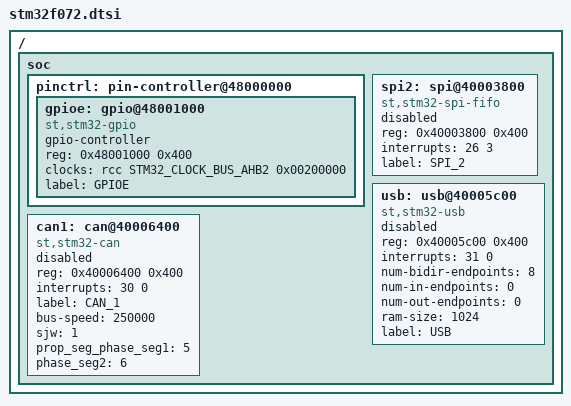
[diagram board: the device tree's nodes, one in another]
/*
 * Copyright (c) 2017 BayLibre, SAS
 *
 * SPDX-License-Identifier: Apache-2.0
 */

#include <st/stm32f0.dtsi>

/ {
	soc {
		pinctrl: pin-controller@48000000 {

			gpioe: gpio@48001000 {
				compatible = "st,stm32-gpio";
				gpio-controller;
				#gpio-cells = <2>;
				reg = <0x48001000 0x400>;
				clocks = <&rcc STM32_CLOCK_BUS_AHB2 0x00200000>;
				label = "GPIOE";
			};
		};

		spi2: spi@40003800 {
			compatible = "st,stm32-spi-fifo";
			#address-cells = <1>;
			#size-cells = <0>;
			reg = <0x40003800 0x400>;
			interrupts = <26 3>;
			status = "disabled";
			label = "SPI_2";
		};

		usb: usb@40005c00 {
			compatible = "st,stm32-usb";
			reg = <0x40005c00 0x400>;
			interrupts = <31 0>;
			interrupt-names = "usb";
			num-bidir-endpoints = <8>;
			num-in-endpoints = <0>;
			num-out-endpoints = <0>;
			ram-size = <1024>;
			status = "disabled";
			label= "USB";
		};

		can1: can@40006400 {
			compatible = "st,stm32-can";
			#address-cells = <1>;
			#size-cells = <0>;
			reg = <0x40006400 0x400>;
			interrupts = <30 0>;
			status = "disabled";
			label = "CAN_1";
			bus-speed = <250000>;
			sjw = <1>;
			prop_seg_phase_seg1 = <5>;
			phase_seg2 = <6>;
		};
	};
};
